# ATmega32HVBrevB device description
Architecture: AVR8; Family: megaAVR
Programming and debug interfaces: ISP, HVPP, debugWIRE
Registers are 8-bit, access not given, no defined reset value unless marked. A register's access mark holds for its fields unless they carry their own. Offsets are from the block's base; lines under a group give offsets from that group; [hi:lo] are bit positions; {n}, {i} and the like mark numbered series; 'fields as' and 'values as' point back to an identical list; <NAME> marks a mode.

## Ordering variants
standard: 3.0 to 4.5 V

## Memory
prog space: start 0x0000 size 0x8000, little endian
  0x0000 FLASH size 0x8000 flash, rw, executable, page 0x80
  0x7e00 BOOT_SECTION_1 size 0x0200 flash, rw, executable, page 0x80
  0x7c00 BOOT_SECTION_2 size 0x0400 flash, rw, executable, page 0x80
  0x7800 BOOT_SECTION_3 size 0x0800 flash, rw, executable, page 0x80
  0x7000 BOOT_SECTION_4 size 0x1000 flash, rw, executable, page 0x80
signatures space: start 0 size 3, little endian
  0 SIGNATURES size 3 signatures, ro
fuses space: start 0 size 0x0002, little endian
  0 FUSES size 0x0002 fuses, rw
lockbits space: start 0 size 0x0001, little endian
  0 LOCKBITS size 0x0001 lockbits, rw
data space: start 0x0000 size 0x0900, little endian
  0x0000 REGISTERS size 0x0020 regs
  0x0020 MAPPED_IO size 0x00e0 io
  0x0100 IRAM size 0x0800 ram
eeprom space: start 0x0000 size 0x0400, little endian
  0x0000 EEPROM size 0x0400 eeprom, rw, page 0x04
io space: start 0x00 size 0x40, little endian

## Peripheral instances (address, pins/pin function, parameters)
ADC at 0x00 — Analog-to-Digital Converter
WDT at 0x00 — Watchdog Timer
FET at 0x00 — FET Control
SPI at 0x00 — Serial Peripheral Interface
EEPROM at 0x00
COULOMB_COUNTER at 0x00
TWI at 0x00 — Two Wire Serial Interface
EXINT at 0x00 — External Interrupts
TC1 at 0x00 — Timer/Counter, 16-bit
TC0 at 0x00 — Timer/Counter, 16-bit
CELL_BALANCING at 0x00
BATTERY_PROTECTION at 0x00
CHARGER_DETECT at 0x00
VOLTAGE_REGULATOR at 0x00
BANDGAP at 0x00
CPU at 0x00 — CPU Registers
  parameters: CORE_VERSION=V2E
PORTA at 0x00 — I/O Port
PORTB at 0x00 — I/O Port
PORTC at 0x00 — I/O Port
BOOT_LOAD at 0x00 — Bootloader
FUSE at 0 in fuses — Fuses
LOCKBIT at 0 in lockbits — Lockbits

## Interrupts
0 RESET — External Pin, Power-on Reset, Brown-out Reset and Watchdog Reset
1 BPINT — Battery Protection Interrupt
2 VREGMON — Voltage regulator monitor interrupt
3 INT0 — External Interrupt Request 0
4 INT1 — External Interrupt Request 1
5 INT2 — External Interrupt Request 2
6 INT3 — External Interrupt Request 3
7 PCINT0 — Pin Change Interrupt 0
8 PCINT1 — Pin Change Interrupt 1
9 WDT — Watchdog Timeout Interrupt
10 BGSCD — Bandgap Buffer Short Circuit Detected
11 CHDET — Charger Detect
12 TIMER1_IC — Timer 1 Input capture
13 TIMER1_COMPA — Timer 1 Compare Match A
14 TIMER1_COMPB — Timer 1 Compare Match B
15 TIMER1_OVF — Timer 1 overflow
16 TIMER0_IC — Timer 0 Input Capture
17 TIMER0_COMPA — Timer 0 Comapre Match A
18 TIMER0_COMPB — Timer 0 Compare Match B
19 TIMER0_OVF — Timer 0 Overflow
20 TWIBUSCD — Two-Wire Bus Connect/Disconnect
21 TWI — Two-Wire Serial Interface
22 SPI_STC — SPI Serial transfer complete
23 VADC — Voltage ADC Conversion Complete
24 CCADC_CONV — Coulomb Counter ADC Conversion Complete
25 CCADC_REG_CUR — Coloumb Counter ADC Regular Current
26 CCADC_ACC — Coloumb Counter ADC Accumulator
27 EE_READY — EEPROM Ready
28 SPM — SPM Ready

## Properties
SIGNATURES: JTAGID=0x9510, SIGNATURE0=0x1e, SIGNATURE1=0x95, SIGNATURE2=0x10
OCD: OCD_REVISION=1, OCD_DATAREG=0x31, PROGBASE=0x0000

## FUSE — Fuses
Instances: FUSE 0 in fuses
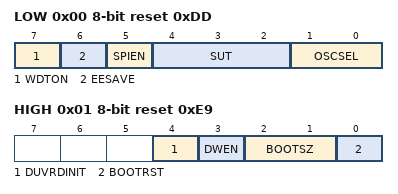
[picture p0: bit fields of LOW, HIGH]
0x00 LOW reset 0xDD
  [7] WDTON — Watch-dog Timer always on
  [6] EESAVE — Preserve EEPROM through the Chip Erase cycle
  [5] SPIEN — Serial program downloading (SPI) enabled
  [4:2] SUT — Select start-up time
    0=14CK_4MS (Start-up time 14 CK + 4 ms); 1=14CK_8MS (Start-up time 14 CK + 8 ms); 2=14CK_16MS (Start-up time 14 CK + 16 ms); 3=14CK_32MS (Start-up time 14 CK + 32 ms); 4=14CK_64MS (Start-up time 14 CK + 64 ms); 5=14CK_128MS (Start-up time 14 CK + 128 ms); 6=14CK_256MS (Start-up time 14 CK + 256 ms); 7=14CK_512MS (Start-up time 14 CK + 512 ms)
  [1:0] OSCSEL — Oscillator select
    1=DEFAULT
0x01 HIGH reset 0xE9
  [4] DUVRDINIT — DUVR mode on
  [3] DWEN — Debug Wire enable
  [2:1] BOOTSZ — Select Boot Size
    3=256W_3F00 (Boot Flash size=256 words Boot address=$3F00); 2=512W_3E00 (Boot Flash size=512 words Boot address=$3E00); 1=1024W_3C00 (Boot Flash size=1024 words Boot address=$3C00); 0=2048W_3800 (Boot Flash size=2048 words Boot address=$3800)
  [0] BOOTRST — Boot Reset vector Enabled
